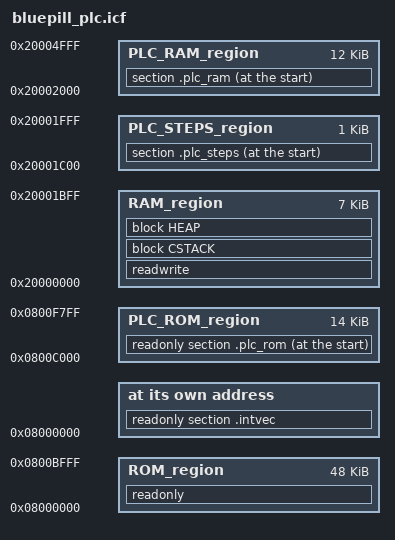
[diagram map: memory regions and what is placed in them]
/* STM32F103C8 BluePill: 64 KB Flash, 20 KB SRAM. */
define symbol __ICFEDIT_intvec_start__ = 0x08000000;
define symbol __ICFEDIT_region_ROM_start__ = 0x08000000;
define symbol __ICFEDIT_region_ROM_end__ = 0x0800BFFF;
define symbol __ICFEDIT_region_RAM_start__ = 0x20000000;
define symbol __ICFEDIT_region_RAM_end__ = 0x20001BFF;
define symbol __ICFEDIT_size_cstack__ = 0x800;
define symbol __ICFEDIT_size_heap__ = 0;

define memory mem with size = 4G;
define region ROM_region = mem:[from __ICFEDIT_region_ROM_start__ to __ICFEDIT_region_ROM_end__];
define region RAM_region = mem:[from __ICFEDIT_region_RAM_start__ to __ICFEDIT_region_RAM_end__];
/* Bounded regions make an oversized PLC section a linker error. */
define region PLC_ROM_region = mem:[from 0x0800C000 to 0x0800F7FF];
define region PLC_STEPS_region = mem:[from 0x20001C00 to 0x20001FFF];
define region PLC_RAM_region = mem:[from 0x20002000 to 0x20004FFF];
define block CSTACK with alignment = 8, size = __ICFEDIT_size_cstack__ { };
define block HEAP with alignment = 8, size = __ICFEDIT_size_heap__ { };

initialize by copy { readwrite };
do not initialize { section .plc_ram, section .plc_steps };
keep { section .plc_rom, section .plc_steps, section .plc_ram };

place at address mem:__ICFEDIT_intvec_start__ { readonly section .intvec };
place at start of PLC_ROM_region { readonly section .plc_rom };
place at start of PLC_STEPS_region { section .plc_steps };
place at start of PLC_RAM_region { section .plc_ram };
place in ROM_region { readonly };
place in RAM_region { readwrite, block CSTACK, block HEAP };

/* 0x0800C000-0x0800F7FF: seven 2 KB PLC program blocks.
 * 0x0800F800-0x0800FFFF: retained data, never allocated by the linker.
 * The .plc_rom factory header is a download image at 0x0800C000; it is
 * not a runtime copy initializer. Downloading it can replace PLC contents
 * in the same flash page. Retained flash has no section or initializer.
 * Fixed PLC RAM/step sections are excluded from ordinary RAM allocation.
 */
